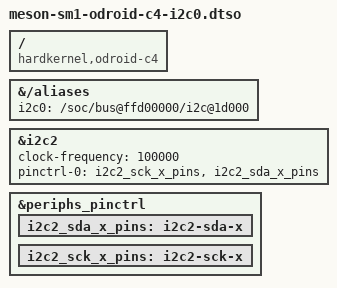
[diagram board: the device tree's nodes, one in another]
/dts-v1/;
/plugin/;

/ {
	compatible = "hardkernel,odroid-c4", "amlogic,sm1";
};

&{/aliases} {
	i2c0 = "/soc/bus@ffd00000/i2c@1d000";
};

&i2c2 {
	status = "okay";
	clock-frequency = <100000>;
	pinctrl-0 = <&i2c2_sck_x_pins &i2c2_sda_x_pins>;
	pinctrl-names = "default";
};

&periphs_pinctrl {
	i2c2_sda_x_pins: i2c2-sda-x { };
	i2c2_sck_x_pins: i2c2-sck-x { };
};
